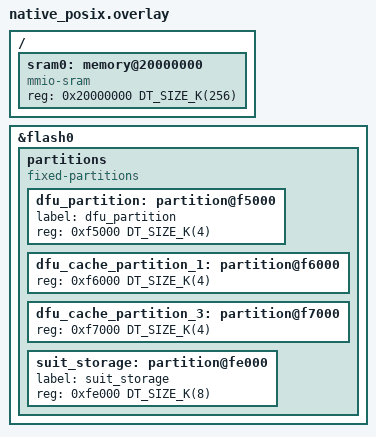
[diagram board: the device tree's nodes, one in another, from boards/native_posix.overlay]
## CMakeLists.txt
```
#
# Copyright (c) 2023 Nordic Semiconductor ASA
#
# SPDX-License-Identifier: LicenseRef-Nordic-5-Clause
#

cmake_minimum_required(VERSION 3.20.0)

find_package(Zephyr REQUIRED HINTS $ENV{ZEPHYR_BASE})

project(platform_test)
include(../cmake/test_template.cmake)

zephyr_library_link_libraries(suit_sink_selector_interface)
zephyr_library_link_libraries(suit_platform_interface)
zephyr_library_link_libraries(suit_stream_sinks_interface)
```

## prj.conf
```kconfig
#
# Copyright (c) 2023 Nordic Semiconductor ASA
#
# SPDX-License-Identifier: LicenseRef-Nordic-5-Clause
#

CONFIG_ZTEST=y

CONFIG_SUIT=y
CONFIG_SUIT_PROCESSOR=y
CONFIG_SUIT_PLATFORM=y
CONFIG_SUIT_PLATFORM_VARIANT_APP=y

CONFIG_SUIT_STREAM=y
CONFIG_SUIT_SINK_SELECTOR=y
CONFIG_SUIT_STREAM_SINK_RAM=y

CONFIG_FLASH=y
CONFIG_SUIT_STREAM_SINK_FLASH=y
CONFIG_FLASH_MAP=y

CONFIG_SUIT_CACHE=y
CONFIG_SUIT_CACHE_RW=y
CONFIG_SUIT_ENVELOPE_INFO=y
CONFIG_SUIT_STREAM_SINK_CACHE=y
CONFIG_SUIT_STREAM_SINK_MEMPTR=y

CONFIG_SUIT_MEMPTR_STORAGE=y
CONFIG_SUIT_UTILS=y
CONFIG_SUIT_METADATA=y

CONFIG_ZCBOR=y
CONFIG_ZCBOR_CANONICAL=y
```

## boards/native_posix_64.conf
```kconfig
#
# Copyright (c) 2023 Nordic Semiconductor ASA
#
# SPDX-License-Identifier: LicenseRef-Nordic-5-Clause
#

CONFIG_FLASH_SIMULATOR=y
```

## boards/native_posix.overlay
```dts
/*
 * Copyright (c) 2023 Nordic Semiconductor ASA
 *
 * SPDX-License-Identifier: LicenseRef-Nordic-5-Clause
 */

&flash0 {
	partitions {
		compatible = "fixed-partitions";
		#address-cells = < 0x1 >;
		#size-cells = < 0x1 >;

		dfu_partition: partition@f5000 {
			label = "dfu_partition";
			reg = < 0xf5000 DT_SIZE_K(4) >;
		};

		dfu_cache_partition_1: partition@f6000 {
			reg = <0xf6000 DT_SIZE_K(4)>;
		};

		dfu_cache_partition_3: partition@f7000 {
			reg = <0xf7000 DT_SIZE_K(4)>;
		};

		/* Use the last 8KB of NVM as suit storage. */
		suit_storage: partition@fe000 {
			label = "suit_storage";
			reg = <0xfe000 DT_SIZE_K(8)>;
		};
	};
};

/ {
	sram0: memory@20000000 {
		compatible = "mmio-sram";
		reg = <0x20000000 DT_SIZE_K(256)>;
	};
};
```

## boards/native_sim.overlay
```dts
/*
 * Copyright (c) 2023 Nordic Semiconductor ASA
 *
 * SPDX-License-Identifier: LicenseRef-Nordic-5-Clause
 */

&flash0 {
	partitions {
		compatible = "fixed-partitions";
		#address-cells = < 0x1 >;
		#size-cells = < 0x1 >;

		dfu_partition: partition@f5000 {
			reg = < 0xf5000 DT_SIZE_K(4) >;
		};

		dfu_cache_partition_1: partition@f6000 {
			reg = <0xf6000 DT_SIZE_K(4)>;
		};

		dfu_cache_partition_3: partition@f7000 {
			reg = <0xf7000 DT_SIZE_K(4)>;
		};

		/* Use the last 8KB of NVM as suit storage. */
		suit_storage: partition@fe000 {
			reg = <0xfe000 DT_SIZE_K(8)>;
		};
	};
};

/ {
	sram0: memory@20000000 {
		compatible = "mmio-sram";
		reg = <0x20000000 DT_SIZE_K(256)>;
	};
};
```

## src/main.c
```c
/*
 * Copyright (c) 2023 Nordic Semiconductor ASA
 *
 * SPDX-License-Identifier: LicenseRef-Nordic-5-Clause
 */

#include <zephyr/ztest.h>
#include <stdint.h>
#include <suit_ram_sink.h>
#include <suit_memptr_sink.h>
#include <suit_flash_sink.h>
#include <suit_sink.h>
#include <suit_sink_selector.h>
#include <suit_platform.h>
#include <suit_platform_internal.h>

#include <suit_types.h>
#include <suit_memptr_storage.h>
#include <suit_platform_internal.h>
#include <zephyr/drivers/flash.h>
#include <zephyr/storage/flash_map.h>

ZTEST_SUITE(sink_selector_tests, NULL, NULL, NULL, NULL, NULL);

ZTEST(sink_selector_tests, test_select_memptr_sink_OK)
{
	suit_component_t handle;
	/* [h'CAND_IMG', h'02'] */
	uint8_t valid_value[] = {0x82, 0x49, 0x68, 'C', 'A',  'N', 'D',
				 '_',  'I',  'M',  'G', 0x41, 0x02};
	struct zcbor_string valid_component_id = {
		.value = valid_value,
		.len = sizeof(valid_value),
	};
	struct stream_sink sink;

	int ret = suit_plat_create_component_handle(&valid_component_id, false, &handle);

	zassert_equal(ret, SUIT_SUCCESS, "create_component_handle failed - error %i", ret);

	int err = suit_sink_select(handle, &sink);

	zassert_equal(err, SUIT_SUCCESS, "sink_selector: selecting memptr_sink failed - error %i",
		      err);
}

ZTEST(sink_selector_tests, test_select_flash_sink_OK)
{
	suit_component_t handle;
	/* [h'MEM', h'02', h'1A00080000', h'191000'] */
	uint8_t valid_value[] = {0x84, 0x44, 0x63, 'M',	 'E',  'M',  0x41, 0x02, 0x45,
				 0x1A, 0x00, 0x08, 0x00, 0x00, 0x43, 0x19, 0x10, 0x00};
	struct zcbor_string valid_component_id = {
		.value = valid_value,
		.len = sizeof(valid_value),
	};
	struct stream_sink sink;

	int ret = suit_plat_create_component_handle(&valid_component_id, false, &handle);

	zassert_equal(ret, SUIT_SUCCESS, "create_component_handle failed - error %i", ret);

	int err = suit_sink_select(handle, &sink);

	zassert_equal(err, SUIT_SUCCESS, "sink_selector: selecting flash_sink failed - error %i",
		      err);
}

ZTEST(sink_selector_tests, test_select_ram_sink_OK)
{
	suit_component_t handle;

	/* ['MEM', h'02', h'1A20000000', h'191000'] */
	uint8_t valid_value[] = {0x84, 0x44, 0x63, 'M',	 'E',  'M',  0x41, 0x02, 0x45,
				 0x1A, 0x20, 0x00, 0x00, 0x00, 0x43, 0x19, 0x10, 0x00};

	struct zcbor_string valid_component_id = {
		.value = valid_value,
		.len = sizeof(valid_value),
	};
	struct stream_sink sink;

	int ret = suit_plat_create_component_handle(&valid_component_id, false, &handle);

	zassert_equal(ret, SUIT_SUCCESS, "create_component_handle failed - error %i", ret);

	int err = suit_sink_select(handle, &sink);

	zassert_equal(err, SUIT_SUCCESS, "sink_selector: selecting flash_sink failed - error %i",
		      err);
}

#if CONFIG_SUIT_STREAM_SINK_SDFW
ZTEST(sink_selector_tests, test_select_sdfw_sink_OK)
{
	suit_component_t handle;
	/* [h'SOC_SPEC', h'01'] */
	uint8_t valid_value[] = {0x82, 0x49, 0x68, 'S', 'O',  'C', '_',
				 'S',  'P',  'E',  'C', 0x41, 0x01};
	struct zcbor_string valid_component_id = {
		.value = valid_value,
		.len = sizeof(valid_value),
	};
	struct stream_sink sink;

	int ret = suit_plat_create_component_handle(&valid_component_id, false, &handle);

	zassert_equal(ret, SUIT_SUCCESS, "create_component_handle failed - error %i", ret);

	int err = suit_sink_select(handle, &sink);

	zassert_equal(err, SUIT_SUCCESS, "sink_selector: selecting swdf_sink failed - error %i",
		      err);
}
#endif

/* Invalid component_id - zcbor wise */
ZTEST(sink_selector_tests, test_select_invalid_component_id)
{
	suit_component_t handle;
	/* [h'MEM', h'02', h'1000080000', h'08'] */
	uint8_t invalid_value[] = {0x84, 0x44, 0x63, 'M',  'E',	 'M',  0x41, 0x02,
				   0x45, 0x10, 0x00, 0x08, 0x00, 0x00, 0x41, 0x08};
	struct zcbor_string invalid_component_id = {
		.value = invalid_value,
		.len = sizeof(invalid_value),
	};

	int ret = suit_plat_create_component_handle(&invalid_component_id, false, &handle);

	zassert_equal(ret, SUIT_ERR_UNSUPPORTED_COMPONENT_ID,
		      "create_component_handle unexpected error %i", ret);
}

/* Invalid component */
ZTEST(sink_selector_tests, test_select_unsupported_component)
{
	suit_component_t handle;
	/* [h'INSTLD_MFST', h'56dc9a1428d852d3bd62e77a08bc8b91'] */
	uint8_t invalid_value[] = {0x82, 0x4c, 0x6b, 'I',  'N',	 'S',  'T',  'L',  'D',	 '_',  'M',
				   'F',	 'S',  'T',  0x50, 0x56, 0xdc, 0x9a, 0x14, 0x28, 0xd8, 0x52,
				   0xd3, 0xbd, 0x62, 0xe7, 0x7a, 0x08, 0xbc, 0x8b, 0x91};
	struct zcbor_string invalid_component_id = {
		.value = invalid_value,
		.len = sizeof(invalid_value),
	};
	struct stream_sink sink;

	int ret = suit_plat_create_component_handle(&invalid_component_id, true, &handle);

	zassert_equal(ret, SUIT_SUCCESS, "create_component_handle failed - error %i", ret);

	int err = suit_sink_select(handle, &sink);

	zassert_not_equal(err, SUIT_SUCCESS,
			  "sink_selector should have failed - unsupported component");
}

ZTEST(sink_selector_tests, test_suit_sink_select_invalid_handle)
{
	suit_component_t handle = 0;
	struct stream_sink sink;

	int err = suit_sink_select(handle, &sink);

	zassert_not_equal(err, SUIT_SUCCESS, "sink_selector should have failed - invalid handle");
}
```
